# PIC32CX1025MTSH128 device description
Architecture: CORTEX-M4; Family: PIC32CXMT; Series: PIC32CXMTSH
Registers are 32-bit, read-write, no defined reset value unless marked. A register's access mark holds for its fields unless they carry their own. Offsets are from the block's base; [hi:lo] are bit positions; {n}, {i} and the like mark numbered series.

## RTT — Real-time Timer
Instances: RTT 0x40053020
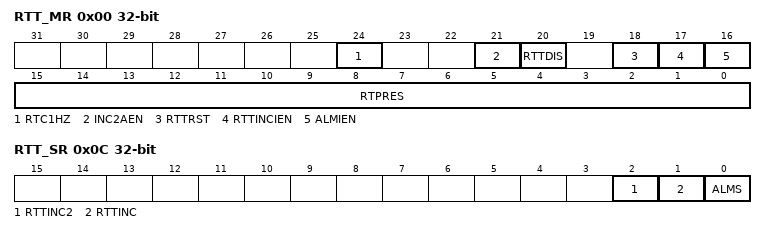
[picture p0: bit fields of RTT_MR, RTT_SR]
0x00 RTT_MR — Mode Register
  [24] RTC1HZ — Real-Time Clock 1Hz Clock Selection
  [21] INC2AEN — RTTINC2 Alarm and Interrupt Enable
  [20] RTTDIS — Real-time Timer Disable
  [18] RTTRST — Real-time Timer Restart
  [17] RTTINCIEN — Real-time Timer Increment Interrupt Enable
  [16] ALMIEN — Alarm Interrupt Enable
  [15:0] RTPRES — Real-time Timer Prescaler Value
0x04 RTT_AR — Alarm Register
  [31:0] ALMV — Alarm Value
0x08 RTT_VR ro — Value Register
  [31:0] CRTV — Current Real-time Value
0x0C RTT_SR ro — Status Register
  [2] RTTINC2 — Predefined Number of Prescaler Roll-overs Status (cleared on read)
  [1] RTTINC — Prescaler Roll-over Status (cleared on read)
  [0] ALMS — Real-time Alarm Status (cleared on read)
0x10 RTT_MODR — Modulo Selection Register
  [2:0] SELINC2 — Selection of the 32-bit Counter Modulo to generate RTTINC2 Flag
    0=NO_RTTINC2 (The RTTINC2 flag never rises); 1=MOD64 (The RTTINC2 flag is set when CRTV modulo 64 equals 0); 2=MOD128 (The RTTINC2 flag is set when CRTV modulo 128 equals 0); 3=MOD256 (The RTTINC2 flag is set when CRTV modulo 256 equals 0); 4=MOD512 (The RTTINC2 flag is set when CRTV modulo 512 equals 0); 5=MOD1024 (The RTTINC2 flag is set when CRTV modulo 1024 equals 0. Example: If RTPRES=32 then RTTINC2 flag rises once per second if the slow clock is 32.768 kHz.); 6=MOD2048 (The RTTINC2 flag is set when CRTV modulo 2048 equals 0); 7=MOD4096 (The RTTINC2 flag is set when CRTV modulo 4096 equals 0)

## SEFC — Secure Embedded Flash Controller
Instances: SEFC0 0x460E0000, SEFC1 0x460E0200
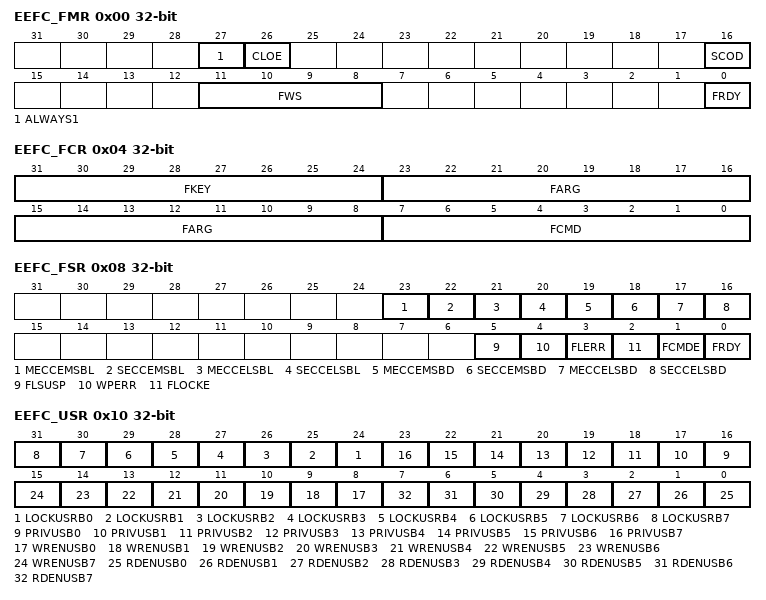
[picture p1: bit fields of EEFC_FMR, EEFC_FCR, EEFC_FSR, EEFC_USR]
0x00 EEFC_FMR — SEFC Flash Mode Register
  [27] ALWAYS1 — Always Written to One
  [26] CLOE — Code Loop Optimization Enable
  [16] SCOD — Sequential Code Optimization Disable
  [11:8] FWS — Flash Wait State
  [0] FRDY — Flash Ready Interrupt Enable
0x04 EEFC_FCR wo — SEFC Flash Command Register
  [31:24] FKEY — Flash Writing Protection Key
    90=PASSWD (The 0x5A value enables the command defined by the bits in the register. If the field is written with a different value, the write is not performed and no action is started.)
  [23:8] FARG — Flash Command Argument
  [7:0] FCMD — Flash Command
    0=GETD (Get Flash descriptor); 1=WP (Write page); 2=WPL (Write page and lock); 7=EPA (Erase pages (8, 16, 32, 64)); 8=SLB (Set lock bit); 9=CLB (Clear lock bit); 10=GLB (Get lock bit); 11=SGPB (Set GPNVM bit); 12=CGPB (Clear GPNVM bit); 13=GGPB (Get GPNVM bit); 14=STUI (Start read unique identifier); 15=SPUI (Stop read unique identifier); 16=GCALB (Get CALIB bit); 17=ES (Erase sector); 18=WUS (Write user signature); 19=EUS (Erase user signature); 20=STUS (Start read user signature); 21=SPUS (Stop read user signature); 23=SUSP (Suspend); 24=RES (Resume); 25=SCK (Send cryptographic key)
0x08 EEFC_FSR ro — SEFC Flash Status Register
  [23] MECCEMSBL — Multiple ECC Error on MSB Part of the Memory Lock Bits
  [22] SECCEMSBL — Single ECC Error on MSB Part of the Memory Lock Bits
  [21] MECCELSBL — Multiple ECC Error on LSB Part of the Memory Lock Bits
  [20] SECCELSBL — Single ECC Error on LSB Part of the Memory Lock Bits
  [19] MECCEMSBD — Multiple ECC Error on MSB Part of the Memory Flash Data Bus (cleared on read)
  [18] SECCEMSBD — Single ECC Error on MSB Part of the Memory Flash Data Bus (cleared on read)
  [17] MECCELSBD — Multiple ECC Error on LSB Part of the Memory Flash Data Bus (cleared on read)
  [16] SECCELSBD — Single ECC Error on LSB Part of the Memory Flash Data Bus (cleared on read)
  [5] FLSUSP — Flash Suspended Status (cleared when resuming the programming operation)
  [4] WPERR — Write Protection Error Status (cleared on read)
  [3] FLERR — Flash Error Status (cleared when a programming operation starts)
  [2] FLOCKE — Flash Lock Error Status (cleared on read or by writing EEFC_FCR)
  [1] FCMDE — Flash Command Error Status (cleared on read)
  [0] FRDY — Flash Ready Status (cleared when Flash is busy)
0x0C EEFC_FRR ro — SEFC Flash Result Register
  [31:0] FVALUE — Flash Result Value
0x10 EEFC_USR — SEFC User Signature Rights Register
  [n+24] LOCKUSRB{n} (n=0..7) — Lock User Signature Rights for User Signature Block {n}
  [n+16] PRIVUSB{n} (n=0..7) — Privileged Access for User Signature Block {n}
  [n+8] WRENUSB{n} (n=0..7) — Write Enable for User Signature Block {n}
  [n] RDENUSB{n} (n=0..7) — Read Enable for User Signature Block {n}
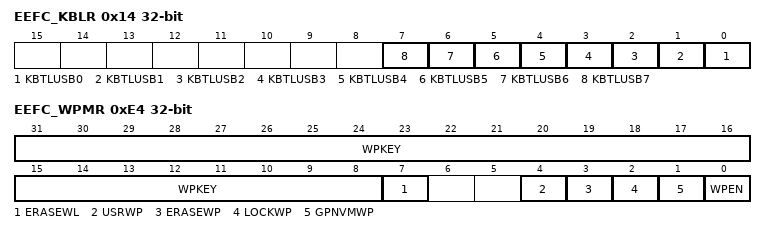
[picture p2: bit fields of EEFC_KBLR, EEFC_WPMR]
0x14 EEFC_KBLR — SEFC Key Bus Lock Register
  [n] KBTLUSB{n} (n=0..7) — Key Bus Transfer Lock from User Signature Block {n}
0xE4 EEFC_WPMR — Write Protection Mode Register
  [31:8] WPKEY — Write Protection Key
    0x454643=PASSWD (Writing any other value in this field aborts the write operation. Always reads as 0.)
  [7] ERASEWL — Erase and Write Lock
  [4] USRWP — User Signature Write Protection
  [3] ERASEWP — Erase and Write Protection
  [2] LOCKWP — Lock Bit Write Protection
  [1] GPNVMWP — GPNVM Bit Write Protection
  [0] WPEN — Write Protection Enable
